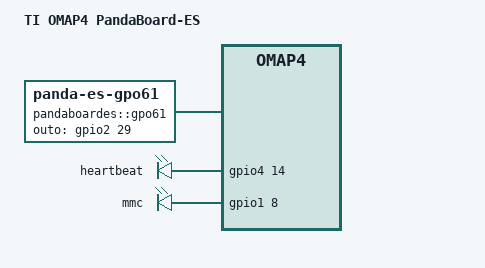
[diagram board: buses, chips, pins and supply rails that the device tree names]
/*
 * Copyright (C) 2012 Texas Instruments Incorporated - http://www.ti.com/
 *
 * This program is free software; you can redistribute it and/or modify
 * it under the terms of the GNU General Public License version 2 as
 * published by the Free Software Foundation.
 */
/dts-v1/;

#include "omap4460.dtsi"
#include "omap4-panda-common.dtsi"

/ {
	model = "TI OMAP4 PandaBoard-ES";
	compatible = "ti,omap4-panda-es", "ti,omap4-panda", "ti,omap4460", "ti,omap4430", "ti,omap4";

	gpo61: gpo61 {
                compatible = "panda-es-gpo61";
                pinctrl-names = "default";
                pinctrl-0 = <
                        &pinmux_test61_pins
                >;

                label = "pandaboardes::gpo61";
                gpio_number = <61>;
                outo-gpios = <&gpio2 29 GPIO_ACTIVE_HIGH>; /* this is <function>-gpios as per Documentation/gpio/board.txt */

                /*
                gpo61_gpios {
                    label = "pandaboardes::gpo61";
                    gpio_number = <61>;
                    outo-gpios = <&gpio2 29 GPIO_ACTIVE_HIGH>;
                };
                */
        };

};

/* Audio routing is differnet between PandaBoard4430 and PandaBoardES */
&sound {
	ti,model = "PandaBoardES";

	/* Audio routing */
	ti,audio-routing =
		"Headset Stereophone", "HSOL",
		"Headset Stereophone", "HSOR",
		"Ext Spk", "HFL",
		"Ext Spk", "HFR",
		"Line Out", "AUXL",
		"Line Out", "AUXR",
		"AFML", "Line In",
		"AFMR", "Line In";
};

&omap4_pmx_core {
    pinmux_test61_pins: pinmux_test61_pins {
        pinctrl-single,pins = <
            OMAP4_IOPAD(0x08a, PIN_OUTPUT | MUX_MODE3)          /* gpio_61 */
        >;
    };
};


/* PandaboardES has external pullups on SCL & SDA */
&dss_hdmi_pins {
	pinctrl-single,pins = <
		OMAP4_IOPAD(0x09a, PIN_INPUT | MUX_MODE0)		/* hdmi_cec.hdmi_cec */
		OMAP4_IOPAD(0x09c, PIN_INPUT | MUX_MODE0)		/* hdmi_scl.hdmi_scl */
		OMAP4_IOPAD(0x09e, PIN_INPUT | MUX_MODE0)		/* hdmi_sda.hdmi_sda */
		>;
};

&omap4_pmx_core {
	led_gpio_pins: gpio_led_pmx {
		pinctrl-single,pins = <
			OMAP4_IOPAD(0x0f6, PIN_OUTPUT | MUX_MODE3)	/* gpio_110 */
		>;
	};
};

&led_wkgpio_pins {
	pinctrl-single,pins = <
		OMAP4_IOPAD(0x05c, PIN_OUTPUT | MUX_MODE3)	/* gpio_wk8 */
	>;
};

&leds {
	pinctrl-0 = <
		&led_gpio_pins
		&led_wkgpio_pins
	>;

	heartbeat {
		gpios = <&gpio4 14 GPIO_ACTIVE_HIGH>;
	};
	mmc {
		gpios = <&gpio1 8 GPIO_ACTIVE_HIGH>;
	};
};

&gpio1 {
	 ti,no-reset-on-init;
};
